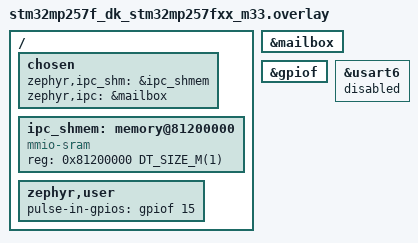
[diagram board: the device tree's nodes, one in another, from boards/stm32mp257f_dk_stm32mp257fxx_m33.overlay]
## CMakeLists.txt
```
cmake_minimum_required(VERSION 3.20.0)

find_package(Zephyr REQUIRED HINTS $ENV{ZEPHYR_BASE})
project(stm32mp257f_m33_app VERSION 2.0.0 LANGUAGES C)

target_include_directories(app PRIVATE ${LIBMETAL_INCLUDE_DIR} ${OPENAMP_INCLUDE_DIR})

target_sources(app PRIVATE
    src/main.c
    src/pulse_gen.c
    src/sampler.c
)
```

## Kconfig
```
mainmenu "STM32MP257F M33 Application"

config APP_USE_STM32_LL_ADC
	bool "Enable STM32 LL ADC for direct ADC3 access"
	default y
	select USE_STM32_LL_ADC
	help
	  Pulls in the STM32 Low-Level ADC driver sources from the HAL so the
	  application can call LL_ADC_* functions directly (without the Zephyr
	  ADC driver framework, which does not yet support the STM32MP2 series).
	  ADC3 is used because it is the only ADC instance assigned to M33/CID2
	  in the default RIFSC configuration; ADC12 is CID1/A35-only.

config APP_USE_STM32_LL_TIM
	bool "Enable STM32 LL TIM for direct TIM2 PWM access"
	default y
	select USE_STM32_LL_TIM
	help
	  Pulls in the STM32 Low-Level timer driver sources so the application
	  can call LL_TIM_* functions directly for 3-phase center-aligned PWM
	  generation on TIM2 (the only general-purpose timer assigned to CID2).

source "Kconfig.zephyr"
```

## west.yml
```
manifest:
  version: "0.13"

  self:
    path: zephyr-app

  remotes:
    - name: zephyrproject
      url-base: https://github.com/zephyrproject-rtos

  projects:
    - name: zephyr
      remote: zephyrproject
      revision: v4.4.0
      import: true       # pulls in all of Zephyr's own west.yml modules

  defaults:
    remote: zephyrproject
```

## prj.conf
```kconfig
# =============================================================================
# STM32MP257F-DK M33 Zephyr — pulse generator application config
# =============================================================================

# --- IPC to Linux A35 via RPMsg/OpenAMP + remoteproc resource table ---
CONFIG_IPM=y
CONFIG_OPENAMP=y
CONFIG_OPENAMP_RSC_TABLE=y
CONFIG_OPENAMP_RSC_TABLE_NUM_RPMSG_BUFF=8
CONFIG_OPENAMP_MASTER=n

# --- Serial: kept enabled but NOT as printk destination (see RAM console below) ---
CONFIG_SERIAL=y
CONFIG_UART_CONSOLE=n

# --- LOG: minimal mode routes LOG_* through printk() → RAM console ---
CONFIG_LOG=y
CONFIG_LOG_MODE_MINIMAL=y
CONFIG_LOG_DEFAULT_LEVEL=3

# --- RAM console: M33 logs visible from Linux via debugfs trace0 ---
CONFIG_RAM_CONSOLE=y
CONFIG_RAM_CONSOLE_BUFFER_SIZE=8192

# --- Heap required by libmetal / OpenAMP ---
CONFIG_HEAP_MEM_POOL_SIZE=65536
CONFIG_MAIN_STACK_SIZE=4096
CONFIG_ISR_STACK_SIZE=4096

# --- GPIO (on-board user LED) ---
CONFIG_GPIO=y

# --- STM32 LL TIM (direct register access for TIM2 PWM) ---
CONFIG_APP_USE_STM32_LL_TIM=y

# --- STM32 LL ADC (direct register access for ADC3, no Zephyr ADC driver) ---
CONFIG_APP_USE_STM32_LL_ADC=y
```

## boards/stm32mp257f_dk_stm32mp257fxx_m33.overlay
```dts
/*
 * Board overlay for STM32MP257F-DK / Cortex-M33 — pulse generator + ADC sampler
 *
 * Defines the shared DDR window used for OpenAMP virtio rings and
 * sets the chosen nodes expected by the openamp_rsc_table subsystem.
 *
 * Address 0x81200000, size 1 MB — must match the Linux remoteproc reservation.
 *
 * Pins used by the application:
 *   PA5  — GPIOA pin 5, RIFSC CID2, AF8 = TIM2_CH4
 *           Hardware PWM output, 0–1 MHz, 50 % duty cycle.
 *           Configured directly in pulse_gen.c via MODER/AFRL registers.
 *   PF15 — GPIOF pin 15, RIFSC CID2, GPIO input with rising-edge EXTI interrupt.
 *           Trigger input: each rising edge fires a software ADC3 conversion.
 *           Declared via zephyr,user node below; read by sampler.c.
 *   PC7  — ADC3 INP9, RIFSC CID1 but stays ANALOG from power-on reset.
 *           Sampled by sampler.c on each PF15 rising edge (no MODER write needed).
 */

/ {
	chosen {
		zephyr,ipc_shm = &ipc_shmem;
		zephyr,ipc     = &mailbox;
	};

	ipc_shmem: memory@81200000 {
		compatible = "mmio-sram";
		reg = <0x81200000 DT_SIZE_M(1)>;
	};

	zephyr,user {
		/* PF15: rising-edge trigger input for ADC sampling (RIFSC CID2) */
		pulse-in-gpios = <&gpiof 15 GPIO_ACTIVE_HIGH>;
	};
};

&mailbox {
	status = "okay";
};

&gpiof {
	status = "okay";
};

/*
 * USART6 defaults to pinctrl on PF13/PF14; disable it so Zephyr does not
 * reconfigure those pins (they are used by Linux on the A35 side).
 */
&usart6 {
	status = "disabled";
};
```

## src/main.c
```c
/*
 * STM32MP257F-DK Cortex-M33 application — pulse generator + triggered ADC sampler.
 *
 * Endpoint "m33-ctrl" (RPMsg / OpenAMP):
 *
 *   Linux → M33 (binary frame):
 *     MSG_TYPE_SET_FREQ  (0x01): freq_hz u32  —  0=stop, 1..1 MHz=run
 *
 *   M33 → Linux (binary frame):
 *     MSG_TYPE_STATUS    (0x02): ts_ms, out_freq_hz, out_enabled, in_freq_hz  at 10 Hz
 *     MSG_TYPE_ADC_CHUNK (0x03): ts_ms + 128 × u16 ADC raw values (as available)
 *     Text heartbeat every 10 s (legacy, for rpmsg-chat.sh)
 *
 *   Text frames (not starting with 0xA5) are echoed back unchanged.
 *
 * Pins:
 *   PA5  — TIM2_CH4 AF8 — pulse generator output (0–1 MHz)
 *   PF15 — GPIO input  — rising-edge trigger for ADC sampling
 *   PC7  — ADC3 INP9   — ADC input sampled on each PF15 rising edge
 */

#include <zephyr/kernel.h>
#include <zephyr/device.h>
#include <zephyr/drivers/ipm.h>
#include <zephyr/drivers/gpio.h>
#include <openamp/open_amp.h>
#include <metal/sys.h>
#include <metal/io.h>
#include <resource_table.h>
#include <addr_translation.h>
#include <zephyr/logging/log.h>
#include <string.h>
#include <stdio.h>

#include "protocol.h"
#include "pulse_gen.h"
#include "sampler.h"

LOG_MODULE_REGISTER(m33_app, LOG_LEVEL_DBG);

#define RPMSG_CHAN_NAME    "m33-ctrl"
#define STATUS_INTERVAL_MS  100    /* 10 Hz status reports */

#if !DT_HAS_CHOSEN(zephyr_ipc_shm)
#error "Add a board overlay with zephyr,ipc_shm and zephyr,ipc chosen nodes"
#endif

#define SHM_NODE       DT_CHOSEN(zephyr_ipc_shm)
#define SHM_START_ADDR DT_REG_ADDR(SHM_NODE)
#define SHM_SIZE       DT_REG_SIZE(SHM_NODE)

#define LED_NODE DT_ALIAS(led0)
#if DT_NODE_HAS_STATUS(LED_NODE, okay)
static const struct gpio_dt_spec led = GPIO_DT_SPEC_GET(LED_NODE, gpios);
#define HAVE_LED 1
#else
#define HAVE_LED 0
#endif

static const struct device *const ipm_dev = DEVICE_DT_GET(DT_CHOSEN(zephyr_ipc));

static metal_phys_addr_t shm_physmap  = SHM_START_ADDR;
static metal_phys_addr_t rsc_physmap;
static struct metal_io_region shm_io_inst;
static struct metal_io_region rsc_io_inst;
static struct metal_io_region *shm_io = &shm_io_inst;
static struct metal_io_region *rsc_io = &rsc_io_inst;

static struct rpmsg_virtio_device rvdev;
static struct rpmsg_device       *rpdev;
static struct rpmsg_endpoint      ctrl_ept;

static K_SEM_DEFINE(vdev_sem,  0, 1);
static K_SEM_DEFINE(bound_sem, 0, 1);

K_THREAD_STACK_DEFINE(mng_stack,    4096);
K_THREAD_STACK_DEFINE(app_stack,    2048);
K_THREAD_STACK_DEFINE(status_stack, 2048);
static struct k_thread mng_thread;
static struct k_thread app_thread;
static struct k_thread status_thread;

/* ── IPM / mailbox ──────────────────────────────────────────────────────────── */

static void ipm_callback(const struct device *dev, void *ctx,
			 uint32_t id, volatile void *data)
{
	ARG_UNUSED(dev); ARG_UNUSED(ctx); ARG_UNUSED(data);
	k_sem_give(&vdev_sem);
}

int mailbox_notify(void *priv, uint32_t id)
{
	ARG_UNUSED(priv);
#if CONFIG_IPM_MAX_DATA_SIZE > 0
	ipm_send(ipm_dev, 0, id, &id, sizeof(id));
#else
	ipm_send(ipm_dev, 0, id, NULL, 0);
#endif
	return 0;
}

/* ── RPMsg endpoint ─────────────────────────────────────────────────────────── */

static int ep_recv(struct rpmsg_endpoint *ept, void *data, size_t len,
		   uint32_t src, void *priv)
{
	ARG_UNUSED(src); ARG_UNUSED(priv);

	const uint8_t *buf = (const uint8_t *)data;

	if (len >= sizeof(struct proto_set_freq_frame) &&
	    buf[0] == PROTO_MAGIC &&
	    buf[1] == MSG_TYPE_SET_FREQ) {

		const struct proto_set_freq_frame *f =
			(const struct proto_set_freq_frame *)buf;
		LOG_INF("SET_FREQ: %u Hz", f->data.freq_hz);
		pulse_gen_set_freq(f->data.freq_hz);
		return RPMSG_SUCCESS;
	}

	/* Legacy: echo text frames back (rpmsg-chat.sh) */
	char echo[128];
	size_t n = MIN(len, sizeof(echo) - 2);
	memcpy(echo, data, n);
	while (n > 0 && (echo[n-1] == '\0' || echo[n-1] == '\n')) { n--; }
	echo[n++] = '\n';
	echo[n]   = '\0';
	LOG_INF("A35→M33: %.*s", (int)(n - 1), echo);
	rpmsg_send(ept, echo, n);
	return RPMSG_SUCCESS;
}

static void ep_unbound(struct rpmsg_endpoint *ept)
{
	ARG_UNUSED(ept);
	pulse_gen_set_freq(0);
	LOG_WRN("RPMsg endpoint unbound — output stopped");
}

static void ns_bind_cb(struct rpmsg_device *rdev, const char *name, uint32_t src)
{
	ARG_UNUSED(rdev);
	LOG_WRN("unexpected NS announcement: %s src=0x%x", name, src);
}

/* ── Platform init ──────────────────────────────────────────────────────────── */

static int platform_init(void)
{
	struct metal_init_params mp = METAL_INIT_DEFAULTS;
	void *rsc_table;
	int rsc_size, ret;

	ret = metal_init(&mp);
	if (ret) { LOG_ERR("metal_init: %d", ret); return ret; }

	metal_io_init(shm_io, (void *)SHM_START_ADDR, &shm_physmap,
		      SHM_SIZE, -1, 0, addr_translation_get_ops(shm_physmap));

	rsc_table_get(&rsc_table, &rsc_size);
	rsc_physmap = (uintptr_t)rsc_table;
	metal_io_init(rsc_io, rsc_table, &rsc_physmap, rsc_size, -1, 0, NULL);

	if (!device_is_ready(ipm_dev)) {
		LOG_ERR("IPM device not ready");
		return -ENODEV;
	}
	ipm_register_callback(ipm_dev, ipm_callback, NULL);
	ipm_set_enabled(ipm_dev, 1);
	return 0;
}

static struct rpmsg_device *platform_create_rpmsg_vdev(void *rsc_table)
{
	struct fw_rsc_vdev_vring *vring;
	struct virtio_device *vdev;
	int ret;

	vdev = rproc_virtio_create_vdev(VIRTIO_DEV_DEVICE, VDEV_ID,
					rsc_table_to_vdev(rsc_table),
					rsc_io, NULL, mailbox_notify, NULL);
	if (!vdev) { LOG_ERR("rproc_virtio_create_vdev failed"); return NULL; }

	rproc_virtio_wait_remote_ready(vdev);

	vring = rsc_table_get_vring0(rsc_table);
	ret = rproc_virtio_init_vring(vdev, 0, vring->notifyid,
				      (void *)vring->da, rsc_io,
				      vring->num, vring->align);
	if (ret) { LOG_ERR("init vring0: %d", ret); goto fail; }

	vring = rsc_table_get_vring1(rsc_table);
	ret = rproc_virtio_init_vring(vdev, 1, vring->notifyid,
				      (void *)vring->da, rsc_io,
				      vring->num, vring->align);
	if (ret) { LOG_ERR("init vring1: %d", ret); goto fail; }

	ret = rpmsg_init_vdev(&rvdev, vdev, ns_bind_cb, shm_io, NULL);
	if (ret) { LOG_ERR("rpmsg_init_vdev: %d", ret); goto fail; }

	return rpmsg_virtio_get_rpmsg_device(&rvdev);

fail:
	rproc_virtio_remove_vdev(vdev);
	return NULL;
}

/* ── Status thread (10 Hz) ──────────────────────────────────────────────────── */

static void status_task(void *a1, void *a2, void *a3)
{
	ARG_UNUSED(a1); ARG_UNUSED(a2); ARG_UNUSED(a3);

	k_sem_take(&bound_sem, K_FOREVER);
	k_sem_give(&bound_sem);

	pulse_gen_init();
	sampler_init();

	uint8_t seq = 0;

	/* Static frame buffer avoids 265-byte stack allocation per loop */
	static struct proto_adc_chunk_frame s_chunk;

	while (1) {
		k_sleep(K_MSEC(STATUS_INTERVAL_MS));

		if (ctrl_ept.dest_addr == RPMSG_ADDR_ANY) {
			continue;
		}

		/* Send STATUS at 10 Hz */
		struct proto_status_frame f = {
			.hdr  = { PROTO_MAGIC, MSG_TYPE_STATUS,
				  PROTO_STATUS_PAYLOAD_LEN, seq++ },
			.data = {
				.ts_ms       = (uint32_t)k_uptime_get(),
				.out_freq_hz = pulse_gen_get_freq(),
				.out_enabled = pulse_gen_is_enabled() ? 1u : 0u,
				.in_freq_hz  = sampler_get_in_freq_hz(),
			},
		};
		rpmsg_send(&ctrl_ept, &f, sizeof(f));

		/* Drain ADC ring buffer — up to 8 chunks per STATUS tick.
		 * At 10 kHz input this handles 1000 samples / 100 ms cleanly. */
		for (int c = 0; c < 8; c++) {
			if (!sampler_read_chunk(s_chunk.data.samples,
						&s_chunk.data.count)) {
				break;
			}
			s_chunk.hdr.magic = PROTO_MAGIC;
			s_chunk.hdr.type  = MSG_TYPE_ADC_CHUNK;
			s_chunk.hdr.len   = PROTO_ADC_CHUNK_PAYLOAD_LEN;
			s_chunk.hdr.seq   = seq++;
			s_chunk.data.ts_ms = (uint32_t)k_uptime_get();
			rpmsg_send(&ctrl_ept, &s_chunk, sizeof(s_chunk));
		}
	}
}

/* ── Application thread: heartbeat ─────────────────────────────────────────── */

static void app_task(void *a1, void *a2, void *a3)
{
	ARG_UNUSED(a1); ARG_UNUSED(a2); ARG_UNUSED(a3);

	k_sem_take(&bound_sem, K_FOREVER);

#if HAVE_LED
	gpio_pin_configure_dt(&led, GPIO_OUTPUT_INACTIVE);
#endif

	uint32_t count = 0;
	char msg[64];

	while (1) {
		if (ctrl_ept.dest_addr != RPMSG_ADDR_ANY) {
			snprintf(msg, sizeof(msg), "M33 heartbeat #%u\n", count++);
			rpmsg_send(&ctrl_ept, msg, strlen(msg));
		}
#if HAVE_LED
		gpio_pin_toggle_dt(&led);
#endif
		k_sleep(K_SECONDS(10));
	}
}

/* ── Management thread ──────────────────────────────────────────────────────── */

static void mng_task(void *a1, void *a2, void *a3)
{
	ARG_UNUSED(a1); ARG_UNUSED(a2); ARG_UNUSED(a3);

	void *rsc_table;
	int rsc_size;

	LOG_INF("STM32MP257F M33 pulse generator starting");

	if (platform_init() < 0) {
		LOG_ERR("platform_init failed");
		return;
	}

	rsc_table_get(&rsc_table, &rsc_size);
	rpdev = platform_create_rpmsg_vdev(rsc_table);
	if (!rpdev) {
		LOG_ERR("platform_create_rpmsg_vdev failed");
		ipm_set_enabled(ipm_dev, 0);
		metal_finish();
		return;
	}

	int ret = rpmsg_create_ept(&ctrl_ept, rpdev, RPMSG_CHAN_NAME,
				   RPMSG_ADDR_ANY, RPMSG_ADDR_ANY,
				   ep_recv, ep_unbound);
	if (ret) {
		LOG_ERR("rpmsg_create_ept: %d", ret);
		ipm_set_enabled(ipm_dev, 0);
		metal_finish();
		return;
	}
	LOG_INF("endpoint '" RPMSG_CHAN_NAME "' ready");
	k_sem_give(&bound_sem);
	k_yield();  /* let status_task run before we drain vdev_sem */

	while (1) {
		k_sem_take(&vdev_sem, K_FOREVER);
		rproc_virtio_notified(rvdev.vdev, VRING1_ID);
	}
}

/* ── Entry point ────────────────────────────────────────────────────────────── */

int main(void)
{
	/* Create highest-priority threads first so they are already waiting on
	 * bound_sem when mng_task eventually gives it.  If mng_task were created
	 * first it would preempt main() (cooperative > preemptive priority) and
	 * give bound_sem before the other threads even exist, causing status_task
	 * to block forever. */
	k_thread_create(&status_thread, status_stack,
			K_THREAD_STACK_SIZEOF(status_stack),
			status_task, NULL, NULL, NULL,
			K_PRIO_COOP(6), 0, K_NO_WAIT);

	k_thread_create(&app_thread, app_stack,
			K_THREAD_STACK_SIZEOF(app_stack),
			app_task, NULL, NULL, NULL,
			K_PRIO_COOP(7), 0, K_NO_WAIT);

	k_thread_create(&mng_thread, mng_stack,
			K_THREAD_STACK_SIZEOF(mng_stack),
			mng_task, NULL, NULL, NULL,
			K_PRIO_COOP(8), 0, K_NO_WAIT);

	return 0;
}
```

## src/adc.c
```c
/*
 * ADC3 driver for STM32MP257F M33 — direct LL HAL access.
 *
 * Peripheral ownership: M33/CID2 (RIFSC ADC3_ID = 59, RIF_CID2, RIF_CFEN).
 * ADC12 (RIFSC ID 58) is CID1/A35-only — do NOT use it from M33.
 *
 * Hardware:
 *   ADC3 (NS) @ 0x404F0000
 *   ADC3_COMMON (NS) @ 0x404F0300
 *   RCC_ADC3CFGR @ 0x442007EC
 *   ch0 = ADC3_INP9 → PC7  (expansion connector, GPIOC CID1, reset-ANALOG)
 *   ch1 = ADC3_INP6 → PF11 (expansion connector, GPIOF CID1, reset-ANALOG)
 *
 * Clock: kernel clock = CK_ICN_LS_MCU (200 MHz), prescaler /16 → fADC 12.5 MHz.
 * Resolution: 12-bit.  Software trigger.  Single-channel per conversion.
 *
 * Note: ADC3 has no internal voltage monitor channels (VDDCORE/VDDCPU are
 * only available on ADC2 which is CID1/A35).  Connect an external voltage
 * to PC7 and/or PF11 on the expansion connector to get non-zero readings.
 */

#include "adc.h"

#include <zephyr/kernel.h>
#include <zephyr/logging/log.h>

#include <stm32mp2xx_ll_adc.h>

LOG_MODULE_REGISTER(m33_adc, LOG_LEVEL_INF);

/* ── Hardware addresses ─────────────────────────────────────────────────── */

/* RCC_BASE_NS = 0x44200000 is defined by CMSIS stm32mp257fxx_cm33.h */

/* ADC3 bus clock + kernel clock select in RCC */
#define RCC_ADC3CFGR         (*(volatile uint32_t *)(RCC_BASE_NS + 0x7ECUL))
#define RCC_ADC3KERSEL_MASK  (3UL << 12)
#define RCC_ADC3KERSEL_ICN   (1UL << 12)  /* CK_ICN_LS_MCU = 0b01 */
#define RCC_ADC3EN           (1UL << 1)

/* GPIOC (PC7 = ADC3_INP9) and GPIOF (PF11 = ADC3_INP6) — both CID1, reset-ANALOG */
#define GPIOC_MODER          (*(volatile uint32_t *)(GPIOC_BASE_NS + 0x00UL))
#define GPIOC_IDR            (*(volatile uint32_t *)(GPIOC_BASE_NS + 0x10UL))
#define GPIOF_MODER          (*(volatile uint32_t *)(GPIOF_BASE_NS + 0x00UL))
#define GPIOF_IDR            (*(volatile uint32_t *)(GPIOF_BASE_NS + 0x10UL))

/* Calibration / enable timeout (in busy-wait loops at ~1 μs/iter) */
#define TIMEOUT_LOOPS        50000U   /* 50 ms */

/* ── Internal helpers ───────────────────────────────────────────────────── */

static int wait_flag_set(volatile uint32_t *reg, uint32_t mask,
			 unsigned int loops)
{
	while (loops--) {
		if (*reg & mask) {
			return 0;
		}
		k_busy_wait(1);
	}
	return -ETIMEDOUT;
}

static int wait_flag_clear(volatile uint32_t *reg, uint32_t mask,
			   unsigned int loops)
{
	while (loops--) {
		if (!(*reg & mask)) {
			return 0;
		}
		k_busy_wait(1);
	}
	return -ETIMEDOUT;
}

/* ── ADC single-channel conversion ─────────────────────────────────────── */

static int read_one(ADC_TypeDef *adc, uint32_t ll_channel, uint16_t *out)
{
	LL_ADC_REG_SetSequencerRanks(adc, LL_ADC_REG_RANK_1, ll_channel);

	/* Clear EOC/OVR/EOS so we wait for THIS conversion, not a stale flag. */
	adc->ISR = ADC_ISR_EOC | ADC_ISR_OVR | ADC_ISR_EOS;

	LL_ADC_REG_StartConversion(adc);

	int rc = wait_flag_set(&adc->ISR, ADC_ISR_EOC, TIMEOUT_LOOPS);

	if (rc < 0) {
		LOG_ERR("ADC EOC timeout (ISR=0x%08x)", adc->ISR);
		LL_ADC_REG_StopConversion(adc);
		return rc;
	}

	*out = (uint16_t)(adc->DR & 0xFFFFU);
	return 0;
}

/* ── Public API ─────────────────────────────────────────────────────────── */

int m33_adc_init(void)
{
	/*
	 * 1. Set GPIO pins to ANALOG mode.
	 *
	 * Do NOT write RCC_GPIOxCFGR here — protected by RCC sub-resource CID
	 * filtering (CID1+semaphore), triggers IAC 156 from M33.  GPIO clocks
	 * are pre-enabled by TF-A.  PC7/PF11 are CID1 pins, so these MODER
	 * writes from M33/CID2 are ignored by RIF — harmless, since both pins
	 * already reset to ANALOG and stay that way (nothing else claims them).
	 */
	GPIOC_MODER |= (3UL << (7 * 2));   /* PC7  = analog (INP9) */
	GPIOF_MODER |= (3UL << (11 * 2));  /* PF11 = analog (INP6) */

	/* Log digital pin states — expected 0 if unconnected, 1 if at 1.8V. */
	LOG_INF("PC7 digital=%u  PF11 digital=%u (0=unconnected/0V, 1=1.8V)",
		(unsigned int)((GPIOC_IDR >> 7) & 1U),
		(unsigned int)((GPIOF_IDR >> 11) & 1U));

	/* 2. Select kernel clock and enable gate.
	 *    ck_flexgen_47 (Linux default, mux=0b00) is unconfigured.
	 *    Use ck_icn_ls_mcu (mux=0b01) — 200 MHz, always running. */
	RCC_ADC3CFGR = (RCC_ADC3CFGR & ~RCC_ADC3KERSEL_MASK) | RCC_ADC3KERSEL_ICN;
	RCC_ADC3CFGR |= RCC_ADC3EN;
	k_busy_wait(5);

	ADC_TypeDef *adc = ADC3_NS;

	/* 3. Exit deep power-down BEFORE touching any ADC register.
	 *    While DEEPPWD=1, all ADC register writes are silently discarded. */
	LL_ADC_DisableDeepPowerDown(adc);
	k_busy_wait(15);

	/* 4. Set prescaler DIV16: 200 MHz / 16 = 12.5 MHz ADC clock. */
	LL_ADC_SetCommonClock(ADC3_COMMON_NS, LL_ADC_CLOCK_DIV16);

	/* 5. Single-ended calibration — non-fatal on timeout.
	 *    Calibration appears to hang on this board (possible VDDA settling
	 *    issue).  Skip and rely on ADRDY to confirm the ADC is functional. */
	LL_ADC_StartCalibration(adc, LL_ADC_SINGLE_ENDED);
	int rc = wait_flag_clear(&adc->CR, ADC_CR_ADCAL, TIMEOUT_LOOPS);

	if (rc < 0) {
		LOG_WRN("ADC3 calibration timeout — skipping");
		LL_ADC_StopCalibration(adc);
		k_busy_wait(5);
	}

	/* 6. Enable ADC */
	LL_ADC_Enable(adc);
	rc = wait_flag_set(&adc->ISR, ADC_ISR_ADRDY, TIMEOUT_LOOPS);
	if (rc < 0) {
		LOG_ERR("ADC3 ADRDY timeout");
		return rc;
	}

	/* 7. One-time sequencer / resolution configuration */
	LL_ADC_REG_SetTriggerSource(adc, LL_ADC_REG_TRIG_SOFTWARE);
	LL_ADC_REG_SetSequencerLength(adc, LL_ADC_REG_SEQ_SCAN_DISABLE);
	LL_ADC_SetResolution(adc, LL_ADC_RESOLUTION_12B);

	/* Pre-select channel 9 (PC7) and channel 6 (PF11) in PCSEL */
	LL_ADC_SetChannelPreselection(adc, LL_ADC_CHANNEL_9);
	LL_ADC_SetChannelPreselection(adc, LL_ADC_CHANNEL_6);

	/* Sampling time: 47.5 cycles (~3.8 μs at 12.5 MHz) */
	LL_ADC_SetChannelSamplingTime(adc, LL_ADC_CHANNEL_9,
				      LL_ADC_SAMPLINGTIME_47CYCLES_5);
	LL_ADC_SetChannelSamplingTime(adc, LL_ADC_CHANNEL_6,
				      LL_ADC_SAMPLINGTIME_47CYCLES_5);

	LOG_INF("ADC3 ready — ch0=PC7/INP9, ch1=PF11/INP6");
	return 0;
}

int m33_adc_read(uint16_t raw[2])
{
	int rc;

	rc = read_one(ADC3_NS, LL_ADC_CHANNEL_9, &raw[0]);
	if (rc < 0) {
		return rc;
	}

	return read_one(ADC3_NS, LL_ADC_CHANNEL_6, &raw[1]);
}
```

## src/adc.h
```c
/*
 * ADC abstraction for STM32MP257F M33.
 *
 * Uses ADC3 (channels 3 & 12) directly via the STM32 LL HAL.
 * ADC3 is the only ADC instance assigned to M33/CID2 in the default RIFSC
 * configuration (ADC12 is CID1/A35-only and must not be accessed from M33).
 *
 * Pins (expansion header CN13):
 *   PG3 → ADC3_INP3  (ch0)   RIFSC GPIOG pin 3: SEM_EN (M33-accessible)
 *   PC3 → ADC3_INP12 (ch1)   RIFSC GPIOC pin 3: CID2   (M33-direct)
 *
 * NOTE: Linux must NOT load an IIO driver for ADC3 (disable the adc3 node
 *       in the Linux DTB, or set status = "disabled").
 */

#ifndef ADC_H
#define ADC_H

#include <stdint.h>

/* Initialise ADC3 and configure both analog input pins.
 * Returns 0 on success, negative errno on failure. */
int m33_adc_init(void);

/* Read both channels in a single call.
 * raw[0] = ADC3_INP3 (PG3), raw[1] = ADC3_INP12 (PC3).
 * Values are 12-bit (0 – 4095).
 * Returns 0 on success, negative errno on timeout/error. */
int m33_adc_read(uint16_t raw[2]);

#endif /* ADC_H */
```

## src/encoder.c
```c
/*
 * Quadrature encoder reader for AMT103-D0500-I5000-S (CUI Devices) on M33.
 *
 * A/B are decoded in software via GPIO EXTI (both-edge) using the standard
 * 4x quadrature state-transition table — no hardware timer encoder mode is
 * available here: the only M33/CID2-accessible general-purpose timer is
 * TIM2, and none of the available CID2 IO candidates map to its TI1/TI2
 * inputs that encoder mode requires.
 *
 * Z (index) is not wired — PF15 is repurposed as encoder A since PF13/PF14
 * are used for phase B/C PWM output.
 *
 * Wiring note: AMT10-series outputs are push-pull at the encoder's supply
 * voltage. Power the encoder from 3.3V (or level-shift A/B down) before
 * connecting it to these GPIOs — STM32 GPIOs are not 5V tolerant here.
 */

#include "encoder.h"

#include <zephyr/kernel.h>
#include <zephyr/drivers/gpio.h>
#include <zephyr/logging/log.h>

LOG_MODULE_REGISTER(m33_encoder, LOG_LEVEL_INF);

#define ENCODER_NODE DT_PATH(zephyr_user)

static const struct gpio_dt_spec a_gpio =
	GPIO_DT_SPEC_GET(ENCODER_NODE, encoder_a_gpios);
static const struct gpio_dt_spec b_gpio =
	GPIO_DT_SPEC_GET(ENCODER_NODE, encoder_b_gpios);

static struct gpio_callback a_cb;
static struct gpio_callback b_cb;

static volatile int32_t position;
static uint8_t ab_state;

/* Quadrature state-transition table, index = (prev_state << 2) | new_state */
static const int8_t QEM[16] = {
	 0, -1, +1,  0,
	+1,  0,  0, -1,
	-1,  0,  0, +1,
	 0, +1, -1,  0,
};

static void ab_changed(const struct device *dev, struct gpio_callback *cb,
		       uint32_t pins)
{
	ARG_UNUSED(dev);
	ARG_UNUSED(cb);
	ARG_UNUSED(pins);

	uint8_t new_state = (uint8_t)((gpio_pin_get_dt(&a_gpio) << 1) |
				       gpio_pin_get_dt(&b_gpio));

	position += QEM[(ab_state << 2) | new_state];
	ab_state = new_state;
}

int m33_encoder_init(void)
{
	int rc;

	if (!gpio_is_ready_dt(&a_gpio) || !gpio_is_ready_dt(&b_gpio)) {
		LOG_ERR("encoder GPIO controller not ready");
		return -ENODEV;
	}

	rc  = gpio_pin_configure_dt(&a_gpio, GPIO_INPUT);
	rc |= gpio_pin_configure_dt(&b_gpio, GPIO_INPUT);
	if (rc) {
		LOG_ERR("encoder GPIO configure failed: %d", rc);
		return rc;
	}

	ab_state = (uint8_t)((gpio_pin_get_dt(&a_gpio) << 1) |
			      gpio_pin_get_dt(&b_gpio));

	gpio_init_callback(&a_cb, ab_changed, BIT(a_gpio.pin));
	gpio_init_callback(&b_cb, ab_changed, BIT(b_gpio.pin));

	gpio_add_callback(a_gpio.port, &a_cb);
	gpio_add_callback(b_gpio.port, &b_cb);

	gpio_pin_interrupt_configure_dt(&a_gpio, GPIO_INT_EDGE_BOTH);
	gpio_pin_interrupt_configure_dt(&b_gpio, GPIO_INT_EDGE_BOTH);

	LOG_INF("encoder ready — A=PF15 B=PG5, 4x quadrature decode (no Z)");
	return 0;
}

int32_t m33_encoder_get_position(void)
{
	return position;
}

uint32_t m33_encoder_get_index_count(void)
{
	return 0;
}

void m33_encoder_reset(void)
{
	position = 0;
}
```

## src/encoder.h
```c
/*
 * Quadrature encoder reader for AMT103-D0500-I5000-S (CUI Devices) on M33.
 *
 * Signals: A = PF13, B = PF14, Z (index, once per revolution) = PF15.
 * All three are GPIOF/RIFSC-CID2 pins, directly configurable from M33.
 */

#ifndef ENCODER_H
#define ENCODER_H

#include <stdint.h>

/* Configure A/B/Z GPIOs and attach EXTI callbacks for quadrature decode.
 * Returns 0 on success, negative errno on failure. */
int m33_encoder_init(void);

/* Signed 4x quadrature position, accumulated since init/last reset. */
int32_t m33_encoder_get_position(void);

/* Number of index (Z) pulses seen since init/last reset. */
uint32_t m33_encoder_get_index_count(void);

/* Zero both counters. */
void m33_encoder_reset(void);

#endif /* ENCODER_H */
```

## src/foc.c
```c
/*
 * Field-Oriented Control (FOC) for 3-phase BLDC motor.
 *
 * Control structure (runs at FOC_FS_HZ = 10 kHz from TIM2 update ISR):
 *
 *   ADC (Ia, Ib) ──► Clarke ──► Park(θ_e) ──► PI(Id,Iq) ──► inv.Park ──► SVPWM
 *                                                                            │
 *   Encoder ──────────────────────────────────────────────────────────────── θ_e
 *
 * Outer loops (run every SPEED_LOOP_DIV FOC cycles = 1 kHz):
 *   Speed mode  : PI speed controller → Iq reference
 *   Angle mode  : P position controller → ω reference → PI speed → Iq reference
 *
 * Current conversion (INA240 bidirectional current sensor):
 *   I = (ADC - ADC_MIDPOINT) × (VREF / 4095) / (GAIN × SHUNT_R)
 *
 * SVPWM uses zero-sequence injection (equivalent to SV-PWM, no sector lookup).
 */

#include "foc.h"
#include "pwm.h"
#include "encoder.h"

#include <math.h>
#include <string.h>
#include <zephyr/kernel.h>
#include <zephyr/logging/log.h>

#include <stm32mp2xx_ll_adc.h>   /* ADC3_NS, LL_ADC_CHANNEL_9/6, etc. */

LOG_MODULE_REGISTER(m33_foc, LOG_LEVEL_INF);

#define SPEED_LOOP_DIV  10U   /* outer loop runs every 10 FOC cycles = 1 kHz */
#define TWO_PI          6.283185307f
#define SQRT3           1.732050808f
#define INV_SQRT3       0.577350269f

/* ── PI controller ─────────────────────────────────────────────────────────── */

typedef struct {
	float kp, ki;
	float integral;
	float out_min, out_max;
} pi_t;

static float pi_step(pi_t *c, float err, float dt)
{
	float out = c->kp * err + c->ki * c->integral;

	/* Clamp with anti-windup: stop integrating when saturated */
	if (out > c->out_max) {
		return c->out_max;
	} else if (out < c->out_min) {
		return c->out_min;
	}
	c->integral += err * dt;
	return out;
}

static void pi_reset(pi_t *c)
{
	c->integral = 0.0f;
}

/* ── Motor state ────────────────────────────────────────────────────────────── */

static volatile uint8_t  cmd_mode;       /* written by RPMsg thread */
static volatile float    cmd_setpoint;   /* written by RPMsg thread */

/* Current PI controllers (d and q axes) */
static pi_t pi_id = { .kp = 2.0f, .ki = 500.0f, .out_min = -VDC_V, .out_max = VDC_V };
static pi_t pi_iq = { .kp = 2.0f, .ki = 500.0f, .out_min = -VDC_V, .out_max = VDC_V };

/* Speed PI controller */
static pi_t pi_spd = { .kp = 0.5f, .ki = 2.0f,
	.out_min = -IQ_MAX_A, .out_max = IQ_MAX_A };

/* Position P controller (gain only, no integral) */
#define KP_POS  3.0f

/* Outer loop rate (rad/s limit to prevent runaway from position P) */
#define OMEGA_MAX  100.0f   /* 100 rad/s mechanical ~ 955 RPM */

static float     iq_ref;    /* q-axis current reference (A) */
static int32_t   prev_enc;  /* encoder position at previous FOC tick */
static uint8_t   outer_cnt; /* outer loop divider counter */
static uint8_t   state;     /* MOTOR_STATE_xxx */

/* Status snapshot (written in ISR, read by RPMsg thread) */
static struct foc_status snap;

/* ── Math helpers ────────────────────────────────────────────────────────────── */

static inline float adc_to_current(uint16_t raw)
{
	float v = ((float)raw - ADC_MIDPOINT) * (ADC_VREF_MV / 1000.0f) / 4095.0f;
	return v / (INA240_GAIN * SHUNT_R_OHMS) * 1000.0f; /* result in mA */
}

static inline float fclampf(float v, float lo, float hi)
{
	return v < lo ? lo : (v > hi ? hi : v);
}

/* Clarke transform: 3-phase → αβ frame (Ic = -Ia - Ib via KCL) */
static inline void clarke(float ia_ma, float ib_ma, float *ialpha, float *ibeta)
{
	*ialpha = ia_ma;
	*ibeta  = (ia_ma + 2.0f * ib_ma) * INV_SQRT3;
}

/* Park transform: αβ → dq rotating frame */
static inline void park(float ia, float ib, float cos_t, float sin_t,
			float *id, float *iq)
{
	*id =  ia * cos_t + ib * sin_t;
	*iq = -ia * sin_t + ib * cos_t;
}

/* Inverse Park: dq → αβ */
static inline void inv_park(float vd, float vq, float cos_t, float sin_t,
			     float *va, float *vb)
{
	*va = vd * cos_t - vq * sin_t;
	*vb = vd * sin_t + vq * cos_t;
}

/*
 * SVPWM via zero-sequence injection.
 * Inputs  : Vα, Vβ (V), Vdc (V)
 * Outputs : duty_a/b/c in [0 … PWM_ARR]
 */
static void svpwm(float valpha, float vbeta, float vdc,
		  uint16_t *da, uint16_t *db, uint16_t *dc)
{
	/* Inverse Clarke to get 3-phase voltages */
	float va =  valpha;
	float vb = -0.5f * valpha + (SQRT3 * 0.5f) * vbeta;
	float vc = -0.5f * valpha - (SQRT3 * 0.5f) * vbeta;

	/* Zero-sequence injection for center-aligned SVM */
	float vmin = va < vb ? (va < vc ? va : vc) : (vb < vc ? vb : vc);
	float vmax = va > vb ? (va > vc ? va : vc) : (vb > vc ? vb : vc);
	float v0   = -(vmin + vmax) * 0.5f;

	float half = vdc * 0.5f;
	float fa = fclampf((va + v0 + half) / vdc, 0.0f, 1.0f);
	float fb = fclampf((vb + v0 + half) / vdc, 0.0f, 1.0f);
	float fc = fclampf((vc + v0 + half) / vdc, 0.0f, 1.0f);

	*da = (uint16_t)(fa * (float)PWM_ARR);
	*db = (uint16_t)(fb * (float)PWM_ARR);
	*dc = (uint16_t)(fc * (float)PWM_ARR);
}

/* ── ADC read for ISR (no k_busy_wait, bare counter loop) ───────────────────── */

static bool foc_adc_read(uint16_t raw[2])
{
	ADC_TypeDef *adc = ADC3_NS;
	uint32_t t;

	/* Channel 9 — PC7 (Ia) */
	LL_ADC_REG_SetSequencerRanks(adc, LL_ADC_REG_RANK_1, LL_ADC_CHANNEL_9);
	adc->ISR = ADC_ISR_EOC | ADC_ISR_OVR | ADC_ISR_EOS;
	LL_ADC_REG_StartConversion(adc);
	for (t = 1000U; t && !(adc->ISR & ADC_ISR_EOC); t--) {
	}
	if (!t) { return false; }
	raw[0] = (uint16_t)(adc->DR & 0xFFFFU);

	/* Channel 6 — PF11 (Ib) */
	LL_ADC_REG_SetSequencerRanks(adc, LL_ADC_REG_RANK_1, LL_ADC_CHANNEL_6);
	adc->ISR = ADC_ISR_EOC | ADC_ISR_OVR | ADC_ISR_EOS;
	LL_ADC_REG_StartConversion(adc);
	for (t = 1000U; t && !(adc->ISR & ADC_ISR_EOC); t--) {
	}
	if (!t) { return false; }
	raw[1] = (uint16_t)(adc->DR & 0xFFFFU);

	return true;
}

/* ── Public API ─────────────────────────────────────────────────────────────── */

int m33_foc_init(void)
{
	cmd_mode     = MOTOR_MODE_OFF;
	cmd_setpoint = 0.0f;
	iq_ref       = 0.0f;
	prev_enc     = m33_encoder_get_position();
	outer_cnt    = 0;
	state        = MOTOR_STATE_OFF;
	memset(&snap, 0, sizeof(snap));

	LOG_INF("FOC init — pole_pairs=%u encoder_cpr=%u fs=%u Hz",
		MOTOR_POLE_PAIRS, ENCODER_CPR, FOC_FS_HZ);
	return 0;
}

void m33_foc_set_command(uint8_t mode, float setpoint)
{
	cmd_mode     = mode;
	cmd_setpoint = setpoint;

	if (mode == MOTOR_MODE_OFF || mode == MOTOR_MODE_OPENLOOP) {
		pi_reset(&pi_id);
		pi_reset(&pi_iq);
		pi_reset(&pi_spd);
		iq_ref = 0.0f;
	}
}

void m33_foc_get_status(struct foc_status *out)
{
	/* Disable IRQ briefly for a consistent snapshot */
	unsigned int key = irq_lock();
	*out = snap;
	irq_unlock(key);
}

/* ── FOC step (called from TIM2 update ISR at 10 kHz) ───────────────────────── */

void m33_foc_step(void)
{
	uint16_t raw[2];
	uint16_t da, db, dc;

	/* --- Open-loop mode: bypass current sensing, apply fixed Vq --------- */
	if (cmd_mode == MOTOR_MODE_OPENLOOP) {
		int32_t enc_now  = m33_encoder_get_position();
		int32_t enc_diff = enc_now - prev_enc;
		prev_enc         = enc_now;

		int32_t pos_mod  = ((enc_now % (int32_t)ENCODER_CPR) + ENCODER_CPR)
				   % (int32_t)ENCODER_CPR;
		float mech_angle = (float)pos_mod * TWO_PI / (float)ENCODER_CPR;
		float speed_rads = (float)enc_diff * TWO_PI / (float)ENCODER_CPR / FOC_DT;
		float elec_angle = fmodf(mech_angle * (float)MOTOR_POLE_PAIRS, TWO_PI);
		float cos_t      = cosf(elec_angle);
		float sin_t      = sinf(elec_angle);

		if (state != MOTOR_STATE_RUN) {
			state = MOTOR_STATE_RUN;
			m33_pwm_enable(true);
		}

		float vq = fclampf(cmd_setpoint, -VDC_V / SQRT3, VDC_V / SQRT3);
		float valpha, vbeta;
		inv_park(0.0f, vq, cos_t, sin_t, &valpha, &vbeta);
		svpwm(valpha, vbeta, VDC_V, &da, &db, &dc);
		m33_pwm_set_duty3(da, db, dc);

		snap.adc_raw[0] = 0;
		snap.adc_raw[1] = 0;
		snap.speed_rads = speed_rads;
		snap.angle_rad  = mech_angle;
		snap.id_ma      = 0.0f;
		snap.iq_ma      = 0.0f;
		snap.state      = state;
		snap.fault      = 0;
		return;
	}

	/* --- Sample currents (closed-loop modes only) ------------------------ */
	if (!foc_adc_read(raw)) {
		state = MOTOR_STATE_FAULT;
		m33_pwm_enable(false);
		return;
	}

	float ia_ma = adc_to_current(raw[0]);
	float ib_ma = adc_to_current(raw[1]);

	/* --- Encoder: mechanical angle and speed ----------------------------- */
	int32_t enc_now  = m33_encoder_get_position();
	int32_t enc_diff = enc_now - prev_enc;
	prev_enc         = enc_now;

	int32_t pos_mod   = ((enc_now % (int32_t)ENCODER_CPR) + ENCODER_CPR)
			    % (int32_t)ENCODER_CPR;
	float mech_angle  = (float)pos_mod * TWO_PI / (float)ENCODER_CPR;
	float speed_rads  = (float)enc_diff * TWO_PI / (float)ENCODER_CPR / FOC_DT;

	/* --- Electrical angle ------------------------------------------------ */
	float elec_angle  = fmodf(mech_angle * (float)MOTOR_POLE_PAIRS, TWO_PI);
	float cos_t = cosf(elec_angle);
	float sin_t = sinf(elec_angle);

	/* --- Clarke → Park --------------------------------------------------- */
	float ialpha, ibeta;
	clarke(ia_ma, ib_ma, &ialpha, &ibeta);

	float id_ma, iq_ma;
	park(ialpha, ibeta, cos_t, sin_t, &id_ma, &iq_ma);
	/* Convert mA → A for PI controllers (iq_ref is in A from IQ_MAX_A) */
	float id_A = id_ma * 0.001f;
	float iq_A = iq_ma * 0.001f;

	/* --- Outer loop (1 kHz) ---------------------------------------------- */
	uint8_t mode = cmd_mode;

	if (++outer_cnt >= SPEED_LOOP_DIV) {
		outer_cnt = 0;
		float dt_outer = FOC_DT * (float)SPEED_LOOP_DIV;

		if (mode == MOTOR_MODE_SPEED) {
			iq_ref = pi_step(&pi_spd, cmd_setpoint - speed_rads, dt_outer);

		} else if (mode == MOTOR_MODE_ANGLE) {
			float angle_err = cmd_setpoint - mech_angle;
			while (angle_err >  3.14159265f) { angle_err -= TWO_PI; }
			while (angle_err < -3.14159265f) { angle_err += TWO_PI; }
			float omega_ref = fclampf(KP_POS * angle_err, -OMEGA_MAX, OMEGA_MAX);
			iq_ref = pi_step(&pi_spd, omega_ref - speed_rads, dt_outer);

		} else {
			iq_ref = 0.0f;
			pi_reset(&pi_spd);
		}
	}

	/* --- Current controllers (inner loop, 10 kHz) ------------------------ */
	if (mode == MOTOR_MODE_OFF) {
		m33_pwm_set_duty3(0, 0, 0);
		if (state == MOTOR_STATE_RUN) {
			m33_pwm_enable(false);
			state = MOTOR_STATE_OFF;
			pi_reset(&pi_id);
			pi_reset(&pi_iq);
		}
	} else {
		if (state != MOTOR_STATE_RUN) {
			state = MOTOR_STATE_RUN;
			m33_pwm_enable(true);
		}

		float vd = pi_step(&pi_id,  0.0f - id_A,       FOC_DT);
		float vq = pi_step(&pi_iq, iq_ref - iq_A,      FOC_DT);

		/* Voltage magnitude limit */
		float v_lim = VDC_V / SQRT3;
		float vmag2 = vd * vd + vq * vq;
		if (vmag2 > v_lim * v_lim) {
			float scale = v_lim / sqrtf(vmag2);
			vd *= scale;
			vq *= scale;
		}

		float valpha, vbeta;
		inv_park(vd, vq, cos_t, sin_t, &valpha, &vbeta);

		svpwm(valpha, vbeta, VDC_V, &da, &db, &dc);
		m33_pwm_set_duty3(da, db, dc);
	}

	/* --- Update status snapshot ------------------------------------------ */
	snap.adc_raw[0] = raw[0];
	snap.adc_raw[1] = raw[1];
	snap.speed_rads = speed_rads;
	snap.angle_rad  = mech_angle;
	snap.id_ma      = id_ma;
	snap.iq_ma      = iq_ma;
	snap.state      = state;
	snap.fault = 0;
}
```

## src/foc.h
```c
#ifndef FOC_H
#define FOC_H

#include <stdint.h>
#include <stdbool.h>

/*
 * Field-Oriented Control (FOC) for 3-phase BLDC motor.
 *
 * Motor parameters — adjust for your motor:
 *   MOTOR_POLE_PAIRS  : electrical / mechanical angle ratio
 *   SHUNT_R_OHMS      : current sense shunt resistance (Ω)
 *   INA240_GAIN       : INA240 amplifier gain (20, 50, 100, or 200 V/V)
 *   VDC_V             : DC bus voltage (V)
 *   IQ_MAX_A          : peak allowed phase current (A)
 */

#define MOTOR_POLE_PAIRS  7U
#define ENCODER_CPR       4096U   /* 4× quadrature × 1024 PPR */
#define FOC_FS_HZ         10000U  /* FOC loop rate (= PWM freq) */
#define FOC_DT            (1.0f / (float)FOC_FS_HZ)

#define SHUNT_R_OHMS      0.01f   /* 10 mΩ */
#define INA240_GAIN       50.0f   /* INA240A2 variant */
#define ADC_VREF_MV       1800.0f /* 1.8 V ADC reference */
#define ADC_MIDPOINT      2048    /* zero-current ADC code (INA240 REF = VCC/2) */
#define VDC_V             24.0f   /* DC bus voltage */
#define IQ_MAX_A          5.0f    /* peak current per axis */

/* Motor control modes */
#define MOTOR_MODE_OFF      0
#define MOTOR_MODE_SPEED    1
#define MOTOR_MODE_ANGLE    2
#define MOTOR_MODE_OPENLOOP 3   /* open-loop: setpoint = q-axis voltage in V */

/* Motor states */
#define MOTOR_STATE_OFF   0
#define MOTOR_STATE_RUN   1
#define MOTOR_STATE_FAULT 2

/* Snapshot of motor state for RPMsg reporting */
struct foc_status {
	uint16_t adc_raw[2];   /* raw ADC readings (IA, IB) */
	float    speed_rads;   /* mechanical speed (rad/s) */
	float    angle_rad;    /* mechanical angle [0, 2π) */
	float    id_ma;        /* d-axis current (mA) */
	float    iq_ma;        /* q-axis current (mA) */
	uint8_t  state;
	uint8_t  fault;
};

/* Initialise FOC — call after PWM and ADC are ready */
int  m33_foc_init(void);

/* Set the control target from RPMsg (called from any thread) */
void m33_foc_set_command(uint8_t mode, float setpoint);

/* Retrieve latest motor status for reporting (thread-safe snapshot) */
void m33_foc_get_status(struct foc_status *out);

/* FOC step — called from TIM2 update ISR at FOC_FS_HZ (ISR-safe only) */
void m33_foc_step(void);

#endif /* FOC_H */
```

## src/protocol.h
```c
/*
 * RPMsg binary protocol — M33 pulse generator ↔ Linux.
 *
 * Frame layout:  [magic:u8][type:u8][len:u8][seq:u8][payload (len bytes)]
 * Text frames (rpmsg-chat.sh) do not start with PROTO_MAGIC and are echoed
 * back unchanged for diagnostic use.
 */

#ifndef PROTOCOL_H
#define PROTOCOL_H

#include <stdint.h>

#define PROTO_MAGIC         0xA5u
#define MSG_TYPE_SET_FREQ   0x01u   /* Linux → M33: set output frequency    */
#define MSG_TYPE_STATUS     0x02u   /* M33 → Linux: current state (~10 Hz)  */
#define MSG_TYPE_ADC_CHUNK  0x03u   /* M33 → Linux: ADC sample batch        */

/* Common 4-byte header */
struct __attribute__((packed)) proto_hdr {
	uint8_t  magic;   /* PROTO_MAGIC */
	uint8_t  type;    /* MSG_TYPE_xxx */
	uint8_t  len;     /* payload bytes following this header */
	uint8_t  seq;     /* 8-bit wrapping counter */
};

/* SET_FREQ payload — Linux → M33 (4 bytes) */
struct __attribute__((packed)) proto_set_freq_payload {
	uint32_t freq_hz;   /* 0 = stop, 1..1 000 000 = run */
};

struct __attribute__((packed)) proto_set_freq_frame {
	struct proto_hdr              hdr;
	struct proto_set_freq_payload data;
};

#define PROTO_SET_FREQ_PAYLOAD_LEN  ((uint8_t)sizeof(struct proto_set_freq_payload))

/* STATUS payload — M33 → Linux (13 bytes) */
struct __attribute__((packed)) proto_status_payload {
	uint32_t ts_ms;       /* k_uptime_get() */
	uint32_t out_freq_hz; /* pulse generator output frequency (0 if stopped) */
	uint8_t  out_enabled; /* 1 = output running, 0 = stopped */
	uint32_t in_freq_hz;  /* measured input frequency on PF15 (0 if no signal) */
};

struct __attribute__((packed)) proto_status_frame {
	struct proto_hdr            hdr;
	struct proto_status_payload data;
};

#define PROTO_STATUS_PAYLOAD_LEN  ((uint8_t)sizeof(struct proto_status_payload))

/* ADC_CHUNK payload — M33 → Linux (261 bytes)
 * Sent whenever SAMPLER_CHUNK_SIZE new ADC samples have accumulated.
 * count is always PROTO_ADC_CHUNK_COUNT; the field is kept for protocol clarity.
 */
#define PROTO_ADC_CHUNK_COUNT  128u   /* must match SAMPLER_CHUNK_SIZE */

struct __attribute__((packed)) proto_adc_chunk_payload {
	uint32_t ts_ms;                          /* timestamp of first sample     */
	uint8_t  count;                          /* valid samples (= CHUNK_COUNT) */
	uint16_t samples[PROTO_ADC_CHUNK_COUNT]; /* ADC raw, 12-bit in 16-bit     */
};

struct __attribute__((packed)) proto_adc_chunk_frame {
	struct proto_hdr               hdr;
	struct proto_adc_chunk_payload data;
};

/* NOTE: sizeof() = 261 bytes which exceeds uint8_t; hdr.len carries 0xFF as sentinel.
 * Python parsers must use the fixed CHUNK_LEN constant, not hdr.len, for ADC chunks. */
#define PROTO_ADC_CHUNK_PAYLOAD_LEN  0xFFu

#endif /* PROTOCOL_H */
```

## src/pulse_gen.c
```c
/*
 * Pulse generator — TIM2 hardware PWM on PA5 (TIM2_CH4, AF8).
 *
 * TIM2 clock = 200 MHz (confirmed from previous FOC calibration:
 *   PSC=0, ARR=9999, centre-aligned mode → 10 kHz ✓ → f_clk = 200 MHz).
 *
 * Edge-aligned up-count:  f_out = f_clk / (ARR + 1)
 *   ARR = (200 MHz / freq_hz) - 1
 *   CCR4 = (ARR + 1) / 2  →  50 % duty cycle
 *
 * No ISR needed — TIM2 generates the waveform autonomously once started.
 */

#include "pulse_gen.h"

#include <zephyr/kernel.h>
#include <zephyr/logging/log.h>
#include <stm32mp2xx_ll_tim.h>

LOG_MODULE_REGISTER(pulse_gen, LOG_LEVEL_INF);

#define TIM_CLK_HZ  200000000UL

/* GPIOA direct register access (non-secure alias) */
#define GPIOA_MODER  (*(volatile uint32_t *)(GPIOA_BASE_NS + 0x00UL))
#define GPIOA_AFRL   (*(volatile uint32_t *)(GPIOA_BASE_NS + 0x20UL))
#define GPIOA_BSRR   (*(volatile uint32_t *)(GPIOA_BASE_NS + 0x18UL))

/* RCC: TIM2 clock gate */
#define RCC_TIM2CFGR  (*(volatile uint32_t *)(RCC_BASE_NS + 0x704UL))
#define RCC_TIM2_EN   (1UL << 1)

/* PA5 bit-field helpers */
#define PA5_MODE_MASK  (3UL    << (5 * 2))
#define PA5_MODE_OUT   (1UL    << (5 * 2))  /* GPIO output */
#define PA5_MODE_AF    (2UL    << (5 * 2))  /* Alternate function */
#define PA5_AF_MASK    (0xFUL  << (5 * 4))
#define PA5_AF8        (8UL    << (5 * 4))  /* AF8 = TIM2_CH4 */
#define PA5_BSRR_CLR   (1UL   << (5 + 16)) /* BSRR reset bit → PA5 LOW */

static volatile uint32_t _freq_hz;

/* ── Public API ─────────────────────────────────────────────────────────────── */

void pulse_gen_init(void)
{
	/* Enable TIM2 bus clock */
	RCC_TIM2CFGR |= RCC_TIM2_EN;
	k_busy_wait(5);

	/* Halt any running counter. Clear DIER before SR: DIER persists across
	 * remoteproc restarts; stale UIE from the previous FOC firmware run
	 * causes a spurious TIM2 interrupt on the next GenerateEvent_UPDATE,
	 * which hits Zephyr's spurious-IRQ handler and silently halts the CPU. */
	LL_TIM_DisableCounter(TIM2_NS);
	TIM2_NS->DIER = 0;
	TIM2_NS->SR   = 0;

	/* Edge-aligned up-count with ARR preload */
	LL_TIM_SetCounterMode(TIM2_NS, LL_TIM_COUNTERMODE_UP);
	LL_TIM_SetPrescaler(TIM2_NS, 0);
	LL_TIM_SetAutoReload(TIM2_NS, 0);
	LL_TIM_EnableARRPreload(TIM2_NS);

	/* CH4 (PA5): PWM mode 1 — output HIGH while CNT < CCR4 */
	LL_TIM_OC_SetMode(TIM2_NS, LL_TIM_CHANNEL_CH4, LL_TIM_OCMODE_PWM1);
	LL_TIM_OC_EnablePreload(TIM2_NS, LL_TIM_CHANNEL_CH4);
	LL_TIM_OC_SetCompareCH4(TIM2_NS, 0);
	LL_TIM_CC_EnableChannel(TIM2_NS, LL_TIM_CHANNEL_CH4);

	/* PA5 starts as GPIO output LOW (TIM2 not yet driving it) */
	GPIOA_MODER = (GPIOA_MODER & ~PA5_MODE_MASK) | PA5_MODE_OUT;
	GPIOA_BSRR  = PA5_BSRR_CLR;

	_freq_hz = 0;

	LOG_INF("pulse_gen init — PA5 idle LOW, TIM2 ready");
}

void pulse_gen_set_freq(uint32_t freq_hz)
{
	if (freq_hz == 0) {
		LL_TIM_DisableCounter(TIM2_NS);
		GPIOA_MODER = (GPIOA_MODER & ~PA5_MODE_MASK) | PA5_MODE_OUT;
		GPIOA_BSRR  = PA5_BSRR_CLR;
		_freq_hz = 0;
		LOG_INF("pulse_gen: stopped, PA5 LOW");
		return;
	}

	if (freq_hz > PULSE_MAX_HZ) {
		freq_hz = PULSE_MAX_HZ;
	}

	uint32_t arr = (TIM_CLK_HZ / freq_hz) - 1;
	uint32_t ccr = (arr + 1) / 2;  /* 50 % duty cycle */

	LL_TIM_DisableCounter(TIM2_NS);
	LL_TIM_SetAutoReload(TIM2_NS, arr);
	LL_TIM_OC_SetCompareCH4(TIM2_NS, ccr);
	LL_TIM_GenerateEvent_UPDATE(TIM2_NS);  /* latch ARR and CCR4 preloads */
	TIM2_NS->SR = 0;
	/* Switch PA5 to AF8 (TIM2_CH4) then start the counter */
	GPIOA_AFRL  = (GPIOA_AFRL  & ~PA5_AF_MASK)   | PA5_AF8;
	GPIOA_MODER = (GPIOA_MODER & ~PA5_MODE_MASK) | PA5_MODE_AF;
	TIM2_NS->CR1 |= TIM_CR1_CEN;
	_freq_hz = freq_hz;
	LOG_INF("pulse_gen: %u Hz  ARR=%u CCR=%u", freq_hz, arr, ccr);
}

uint32_t pulse_gen_get_freq(void)   { return _freq_hz; }
bool     pulse_gen_is_enabled(void) { return _freq_hz > 0; }
```

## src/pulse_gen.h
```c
/*
 * Pulse generator — 50 % duty-cycle square wave on PA5 (TIM2_CH4, AF8).
 *
 * TIM2 runs in edge-aligned up-count mode; no ISR required.
 * PA5 is held LOW as GPIO output when the generator is stopped.
 */

#ifndef PULSE_GEN_H
#define PULSE_GEN_H

#include <stdint.h>
#include <stdbool.h>

#define PULSE_MAX_HZ  1000000UL   /* 1 MHz upper limit */

/* Initialise TIM2 and PA5.  Output starts disabled (PA5 held LOW). */
void     pulse_gen_init(void);

/* Set output frequency in Hz.  0 = disable (PA5 LOW).
 * Values above PULSE_MAX_HZ are clamped to PULSE_MAX_HZ. */
void     pulse_gen_set_freq(uint32_t freq_hz);

uint32_t pulse_gen_get_freq(void);
bool     pulse_gen_is_enabled(void);

#endif /* PULSE_GEN_H */
```

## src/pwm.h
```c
#ifndef PWM_H
#define PWM_H

#include <stdint.h>
#include <stdbool.h>

/*
 * 3-phase center-aligned PWM via TIM2 (CID2, APB1).
 *
 * Pin assignment (all CID2):
 *   PA5  → TIM2_CH1 AF1  — Phase A  (hardware PWM)
 *   PF13 → GPIO output   — Phase B  (software PWM, CH2 compare ISR)
 *   PF14 → GPIO output   — Phase C  (software PWM, CH3 compare ISR)
 *   EN   — no pin; tie bridge enable to 3V3, use duty=0 to disable
 *
 * Switching frequency: 10 kHz (center-aligned, ARR = 9999 @ 200 MHz).
 * FOC callback fires at 10 kHz from the TIM2 update interrupt.
 */

#define PWM_ARR      9999U    /* TIM2 auto-reload value */
#define PWM_FREQ_HZ  10000U   /* resulting switching frequency */

/* Called from TIM2 update ISR at 10 kHz — must not call Zephyr blocking APIs */
typedef void (*pwm_foc_cb_t)(void);

/* Configure TIM2 and GPIOs — does NOT start the counter or ISR */
int  m33_pwm_init(pwm_foc_cb_t foc_cb);
/* Start TIM2 counter — ISR begins firing at 10 kHz from this call */
void m33_pwm_start(void);
void m33_pwm_set_duty3(uint16_t a, uint16_t b, uint16_t c); /* 0 … PWM_ARR */
void m33_pwm_enable(bool en);
/* Diagnostic — returns last duty values written, enabled flag, and GPIOF ODR */
void m33_pwm_get_state(uint16_t *a, uint16_t *b, uint16_t *c, bool *en,
		       uint32_t *gpiof_odr);

#endif /* PWM_H */
```
